AUTOSAR XML (schema 4-2-2)
package /Components
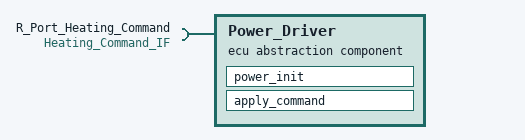
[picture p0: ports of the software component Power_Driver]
  ecu abstraction sw component type Power_Driver
    require port R_Port_Heating_Command: required-interface=Heating_Command_IF
    behavior Power_Driver_Internal
      data received event command_received_event: start-on-event=apply_command
      init event power_init_event: start-on-event=power_init
      runnable power_init: symbol=Power_Driver_power_init
        data-read-access:
          access VA_Init_Read_Seat1_Command_Level: accessed-variable=R_Port_Heating_Command.Seat1_Command_Level
          access VA_Init_Read_Seat2_Command_Level: accessed-variable=R_Port_Heating_Command.Seat2_Command_Level
      runnable apply_command: symbol=Power_Driver_apply_command
        data-receive-point-by-values:
          access VA_Rx_Seat1_Command_Level: accessed-variable=R_Port_Heating_Command.Seat1_Command_Level
          access VA_Rx_Seat2_Command_Level: accessed-variable=R_Port_Heating_Command.Seat2_Command_Level
